# LINTCHIP register map
Vendor: Test; File version: 0.1
lint 测试夹具：包含重叠、越界、重复名与中断号冲突
CPU: CM0
Registers are 32-bit, read-write, reset 0x0 unless marked. A register's access mark holds for its fields unless they carry their own. Offsets are from the block's base; lines under a group give offsets from that group; [hi:lo] are bit positions; {n}, {i} and the like mark numbered series; 'fields as' and 'values as' point back to an identical list; <NAME> marks a mode.

## Memory map
0x40000000 REG — 寄存器问题合集
0x40001000 OTHER — 中断号与 REG 的 IRQX 冲突

## Interrupts
5 IRQX (REG)
7 IRQX (OTHER)

## REG — 寄存器问题合集
Base 0x40000000
0x00 REGA — 4 字节，与 REGB 重叠
0x02 REGB — 起始地址落在 REGA 内
0x10 DUP
0x20 dup — 与 DUP 仅是大小写不同（重复名）
0x30 REGC — 位域重叠与越界
  [35:32] BIG — 超出 32 位寄存器范围
  [5:3] F2 — 与 F1 在 bit3 重叠
  [3:0] F1
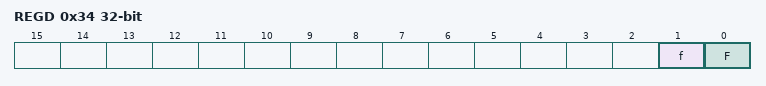
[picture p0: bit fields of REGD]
0x34 REGD — 位域名仅大小写不同
  [1] f, [0] F
0x38 REGE reset 0x1FFFFFFFF — 复位值超出 32 位
0x40 ALIAS_A — 同一偏移的两个视图之一（合法写法，应记为 info）
0x40 ALIAS_B — 同一偏移的两个视图之二（合法写法，应记为 info）
0x50 REGV32 — 32 位视图（合法写法，与其中包含的 8 位视图应记为 info）
0x53 REGV8 8-bit — 8 位视图（完全落在 32 位视图内，应记为 info）
0x60 REGF — 位域别名的容器（WIDE 与其中的 BIT2 应记为 info）
  [2] BIT2, [7:0] WIDE
